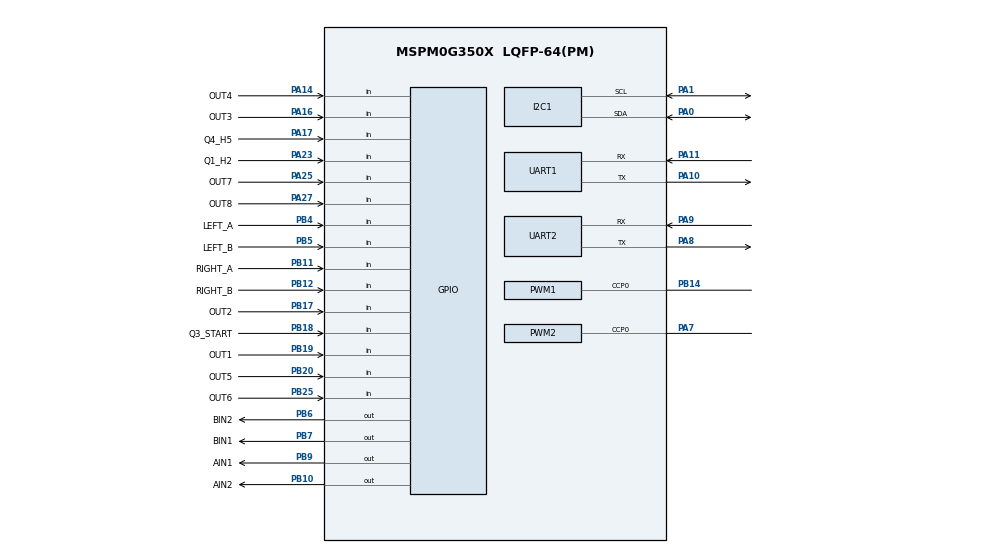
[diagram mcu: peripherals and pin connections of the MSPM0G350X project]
/**
 * @cliArgs --device "MSPM0G350X" --part "Default" --package "LQFP-64(PM)" --product "mspm0_sdk@2.10.00.04"
 * @versions {"tool":"1.27.1+4634"}
 */

/**
 * Import the modules used in this configuration.
 */
const GPIO   = scripting.addModule("/ti/driverlib/GPIO", {}, false);
const GPIO1  = GPIO.addInstance();
const GPIO2  = GPIO.addInstance();
const GPIO3  = GPIO.addInstance();
const GPIO4  = GPIO.addInstance();
const I2C    = scripting.addModule("/ti/driverlib/I2C", {}, false);
const I2C1   = I2C.addInstance();
const PWM    = scripting.addModule("/ti/driverlib/PWM", {}, false);
const PWM1   = PWM.addInstance();
const PWM2   = PWM.addInstance();
const SYSCTL = scripting.addModule("/ti/driverlib/SYSCTL");
const TIMER  = scripting.addModule("/ti/driverlib/TIMER", {}, false);
const TIMER1 = TIMER.addInstance();
const UART   = scripting.addModule("/ti/driverlib/UART", {}, false);
const UART1  = UART.addInstance();
const UART2  = UART.addInstance();

/**
 * Write custom configuration values to the imported modules.
 */
const gate7  = system.clockTree["MFCLKGATE"];
gate7.enable = true;

GPIO1.$name                         = "MOTOR_DIR";
GPIO1.associatedPins.create(4);
GPIO1.associatedPins[0].$name       = "AIN1";
GPIO1.associatedPins[0].pin.$assign = "PB9";
GPIO1.associatedPins[1].$name       = "AIN2";
GPIO1.associatedPins[1].pin.$assign = "PB10";
GPIO1.associatedPins[2].$name       = "BIN1";
GPIO1.associatedPins[2].pin.$assign = "PB7";
GPIO1.associatedPins[3].$name       = "BIN2";
GPIO1.associatedPins[3].pin.$assign = "PB6";

const Board = scripting.addModule("/ti/driverlib/Board", {}, false);

GPIO2.$name                              = "ENCODER";
GPIO2.associatedPins.create(4);
GPIO2.associatedPins[0].$name            = "RIGHT_A";
GPIO2.associatedPins[0].direction        = "INPUT";
GPIO2.associatedPins[0].internalResistor = "PULL_UP";
GPIO2.associatedPins[0].interruptEn      = true;
GPIO2.associatedPins[0].polarity         = "RISE_FALL";
GPIO2.associatedPins[0].pin.$assign      = "PB11";
GPIO2.associatedPins[1].$name            = "RIGHT_B";
GPIO2.associatedPins[1].direction        = "INPUT";
GPIO2.associatedPins[1].internalResistor = "PULL_UP";
GPIO2.associatedPins[1].pin.$assign      = "PB12";
GPIO2.associatedPins[2].$name            = "LEFT_A";
GPIO2.associatedPins[2].direction        = "INPUT";
GPIO2.associatedPins[2].internalResistor = "PULL_UP";
GPIO2.associatedPins[2].interruptEn      = true;
GPIO2.associatedPins[2].polarity         = "RISE_FALL";
GPIO2.associatedPins[2].pin.$assign      = "PB4";
GPIO2.associatedPins[3].$name            = "LEFT_B";
GPIO2.associatedPins[3].direction        = "INPUT";
GPIO2.associatedPins[3].internalResistor = "PULL_UP";
GPIO2.associatedPins[3].pin.$assign      = "PB5";

GPIO3.$name                              = "LINE";
GPIO3.associatedPins.create(8);
GPIO3.associatedPins[0].$name            = "OUT1";
GPIO3.associatedPins[0].direction        = "INPUT";
GPIO3.associatedPins[0].internalResistor = "PULL_UP";
GPIO3.associatedPins[0].pin.$assign      = "PB19";
GPIO3.associatedPins[1].$name            = "OUT2";
GPIO3.associatedPins[1].direction        = "INPUT";
GPIO3.associatedPins[1].internalResistor = "PULL_UP";
GPIO3.associatedPins[1].pin.$assign      = "PB17";
GPIO3.associatedPins[2].$name            = "OUT3";
GPIO3.associatedPins[2].direction        = "INPUT";
GPIO3.associatedPins[2].internalResistor = "PULL_UP";
GPIO3.associatedPins[2].pin.$assign      = "PA16";
GPIO3.associatedPins[3].$name            = "OUT4";
GPIO3.associatedPins[3].direction        = "INPUT";
GPIO3.associatedPins[3].internalResistor = "PULL_UP";
GPIO3.associatedPins[3].pin.$assign      = "PA14";
GPIO3.associatedPins[4].$name            = "OUT5";
GPIO3.associatedPins[4].direction        = "INPUT";
GPIO3.associatedPins[4].internalResistor = "PULL_UP";
GPIO3.associatedPins[4].pin.$assign      = "PB20";
GPIO3.associatedPins[5].$name            = "OUT6";
GPIO3.associatedPins[5].direction        = "INPUT";
GPIO3.associatedPins[5].internalResistor = "PULL_UP";
GPIO3.associatedPins[5].pin.$assign      = "PB25";
GPIO3.associatedPins[6].$name            = "OUT7";
GPIO3.associatedPins[6].direction        = "INPUT";
GPIO3.associatedPins[6].internalResistor = "PULL_UP";
GPIO3.associatedPins[6].pin.$assign      = "PA25";
GPIO3.associatedPins[7].$name            = "OUT8";
GPIO3.associatedPins[7].direction        = "INPUT";
GPIO3.associatedPins[7].internalResistor = "PULL_UP";
GPIO3.associatedPins[7].pin.$assign      = "PA27";

GPIO4.$name                              = "USER_KEY";
GPIO4.associatedPins.create(3);
GPIO4.associatedPins[0].$name            = "Q1_H2";
GPIO4.associatedPins[0].direction        = "INPUT";
GPIO4.associatedPins[0].internalResistor = "PULL_UP";
GPIO4.associatedPins[0].interruptEn      = false;
GPIO4.associatedPins[0].polarity         = "FALL";
GPIO4.associatedPins[0].pin.$assign      = "PA23";
GPIO4.associatedPins[1].$name            = "Q3_START";
GPIO4.associatedPins[1].direction        = "INPUT";
GPIO4.associatedPins[1].internalResistor = "PULL_UP";
GPIO4.associatedPins[1].interruptEn      = false;
GPIO4.associatedPins[1].polarity         = "FALL";
GPIO4.associatedPins[1].pin.$assign      = "PB18";
GPIO4.associatedPins[2].$name            = "Q4_H5";
GPIO4.associatedPins[2].direction        = "INPUT";
GPIO4.associatedPins[2].internalResistor = "PULL_UP";
GPIO4.associatedPins[2].interruptEn      = false;
GPIO4.associatedPins[2].polarity         = "FALL";
GPIO4.associatedPins[2].pin.$assign      = "PA17";

I2C1.$name                             = "I2C_DISPLAY";
I2C1.basicEnableController             = true;
I2C1.peripheral.$assign                = "I2C0";
I2C1.peripheral.sdaPin.$assign         = "PA0";
I2C1.peripheral.sclPin.$assign         = "PA1";
I2C1.sdaPinConfig.$name                = "ti_driverlib_gpio_GPIOPinGeneric0";
I2C1.sdaPinConfig.hideOutputInversion  = scripting.forceWrite(false);
I2C1.sdaPinConfig.onlyInternalResistor = scripting.forceWrite(false);
I2C1.sdaPinConfig.passedPeripheralType = scripting.forceWrite("Digital");
I2C1.sclPinConfig.$name                = "ti_driverlib_gpio_GPIOPinGeneric1";
I2C1.sclPinConfig.hideOutputInversion  = scripting.forceWrite(false);
I2C1.sclPinConfig.onlyInternalResistor = scripting.forceWrite(false);
I2C1.sclPinConfig.passedPeripheralType = scripting.forceWrite("Digital");

PWM1.$name                              = "PWM_RIGHT";
PWM1.timerStartTimer                    = true;
PWM1.timerCount                         = 2000;
PWM1.pwmMode                            = "EDGE_ALIGN_UP";
PWM1.ccIndex                            = [0];
PWM1.PWM_CHANNEL_0.$name                = "ti_driverlib_pwm_PWMTimerCC0";
PWM1.ccp0PinConfig.$name                = "ti_driverlib_gpio_GPIOPinGeneric2";
PWM1.ccp0PinConfig.direction            = scripting.forceWrite("OUTPUT");
PWM1.ccp0PinConfig.hideOutputInversion  = scripting.forceWrite(false);
PWM1.ccp0PinConfig.onlyInternalResistor = scripting.forceWrite(false);
PWM1.ccp0PinConfig.passedPeripheralType = scripting.forceWrite("Digital");
PWM1.peripheral.$assign                 = "TIMA0";
PWM1.peripheral.ccp0Pin.$assign         = "PB14";

PWM2.$name                              = "PWM_LEFT";
PWM2.timerStartTimer                    = true;
PWM2.timerCount                         = 2000;
PWM2.pwmMode                            = "EDGE_ALIGN_UP";
PWM2.ccIndex                            = [0];
PWM2.PWM_CHANNEL_0.$name                = "ti_driverlib_pwm_PWMTimerCC1";
PWM2.ccp0PinConfig.$name                = "ti_driverlib_gpio_GPIOPinGeneric4";
PWM2.ccp0PinConfig.direction            = scripting.forceWrite("OUTPUT");
PWM2.ccp0PinConfig.hideOutputInversion  = scripting.forceWrite(false);
PWM2.ccp0PinConfig.onlyInternalResistor = scripting.forceWrite(false);
PWM2.ccp0PinConfig.passedPeripheralType = scripting.forceWrite("Digital");
PWM2.peripheral.$assign                 = "TIMG8";
PWM2.peripheral.ccp0Pin.$assign         = "PA7";

SYSCTL.forceDefaultClkConfig = true;
SYSCTL.clockTreeEn           = true;

TIMER1.$name              = "CONTROL_TIMER";
TIMER1.timerMode          = "PERIODIC_UP";
TIMER1.timerPeriod        = "1ms";
TIMER1.interrupts         = ["LOAD"];
TIMER1.timerStartTimer    = true;
TIMER1.peripheral.$assign = "TIMA1";

UART1.$name                            = "DEBUG_UART";
UART1.uartClkSrc                       = "MFCLK";
UART1.enabledInterrupts                = ["RX"];
UART1.targetBaudRate                   = 115200;
UART1.peripheral.$assign               = "UART0";
UART1.peripheral.rxPin.$assign         = "PA11";
UART1.peripheral.txPin.$assign         = "PA10";
UART1.txPinConfig.direction            = scripting.forceWrite("OUTPUT");
UART1.txPinConfig.hideOutputInversion  = scripting.forceWrite(false);
UART1.txPinConfig.onlyInternalResistor = scripting.forceWrite(false);
UART1.txPinConfig.passedPeripheralType = scripting.forceWrite("Digital");
UART1.txPinConfig.$name                = "ti_driverlib_gpio_GPIOPinGeneric20";
UART1.rxPinConfig.hideOutputInversion  = scripting.forceWrite(false);
UART1.rxPinConfig.onlyInternalResistor = scripting.forceWrite(false);
UART1.rxPinConfig.passedPeripheralType = scripting.forceWrite("Digital");
UART1.rxPinConfig.$name                = "ti_driverlib_gpio_GPIOPinGeneric21";

UART2.$name                            = "VISION_UART";
UART2.uartClkSrc                       = "MFCLK";
UART2.enabledInterrupts                = ["BREAK_ERROR","FRAMING_ERROR","NOISE_ERROR","OVERRUN_ERROR","PARITY_ERROR","RX"];
UART2.targetBaudRate                   = 115200;
UART2.peripheral.$assign               = "UART1";
UART2.peripheral.rxPin.$assign         = "PA9";
UART2.peripheral.txPin.$assign         = "PA8";
UART2.txPinConfig.direction            = scripting.forceWrite("OUTPUT");
UART2.txPinConfig.hideOutputInversion  = scripting.forceWrite(false);
UART2.txPinConfig.onlyInternalResistor = scripting.forceWrite(false);
UART2.txPinConfig.passedPeripheralType = scripting.forceWrite("Digital");
UART2.txPinConfig.$name                = "ti_driverlib_gpio_GPIOPinGeneric22";
UART2.rxPinConfig.hideOutputInversion  = scripting.forceWrite(false);
UART2.rxPinConfig.onlyInternalResistor = scripting.forceWrite(false);
UART2.rxPinConfig.passedPeripheralType = scripting.forceWrite("Digital");
UART2.rxPinConfig.$name                = "ti_driverlib_gpio_GPIOPinGeneric23";

/**
 * Pinmux solution for unlocked pins/peripherals. This ensures that minor changes to the automatic solver in a future
 * version of the tool will not impact the pinmux you originally saw.  These lines can be completely deleted in order to
 * re-solve from scratch.
 */
Board.peripheral.$suggestSolution          = "DEBUGSS";
Board.peripheral.swclkPin.$suggestSolution = "PA20";
Board.peripheral.swdioPin.$suggestSolution = "PA19";
